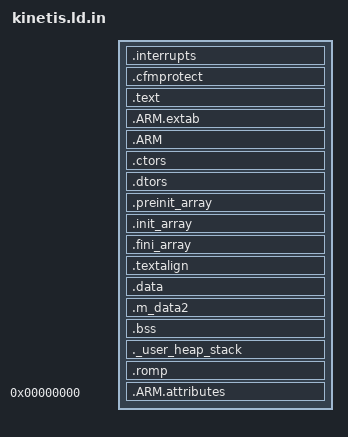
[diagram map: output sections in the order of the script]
/* ################################################################### */
/*##
/*##     This component was generated by some crappy tool and I modified
/*##     it to work with the K20 we are using. Deal with it.
/*##     This is now for the MK20DX128VLH7 with 128k flash and 32k SRAM
/*##     - Ben Nahill<bnahill@gmail.com>
/*## 
/*##     THIS COMPONENT MODULE IS GENERATED BY THE TOOL. DO NOT MODIFY IT. */
/*##                                   */
/*##     Filename  : ProcessorExpert.ld */
/*##                                   */
/*##     Project   : ProcessorExpert   */
/*##                                   */
/*##     Processor : MK40DX256ZVLQ10   */
/*##                                   */
/*##     Compiler  : GNU C Compiler    */
/*##                                   */
/*##     Date/Time : 2013-02-26, 17:01, # CodeGen: 8 */
/*##                                   */
/*##     Abstract  :                   */
/*##                                   */
/*##     This file is used by the linker. It describes files to be linked, */
/*##     memory ranges, stack size, etc. For detailed description about linker */
/*##     command files see compiler documentation. This file is generated by default. */
/*##     You can switch off generation by setting the property "Generate linker file = no" */
/*##     in the "Build options" tab of the CPU component and then modify this file as needed. */
/*##
/*##                                   */
/*## ###################################################################*/


/* Entry Point */
ENTRY(__reset_vector)

/* Highest address of the user mode stack */
_estack = 0x20000000;    /* end of m_data */
__SP_INIT = _estack;
__stack = _estack; /* For newlib */

/* Generate a link error if heap and stack don't fit into RAM */
__heap_size = 2k;                 /* required amount of heap  */
__stack_size = 8k;                 /* required amount of stack */


MEMORY {
  /* Vector addresses in the first 1K */
  m_interrupts (RX) : ORIGIN = 0x00000000, LENGTH = 1k
  /* Then some flash protection crap */
  m_cfmprotrom  (RX) : ORIGIN = 0x00000400, LENGTH = 16
  /* Then the flash we actually want */
  m_text      (RX) : ORIGIN = 1k + 32, LENGTH = ${FLASH_SIZE} - 32
  /* There are two RAM regions... They are centered around 0x20000000 */
  m_data      (RW) : ORIGIN = 0x20000000 - ${SRAM_BANK_SIZE}, LENGTH = ${SRAM_BANK_SIZE}
  /* To avoid variables crossing this boundary, they are separated.
   * Hopefully this won't screw something up.
   */
  m_data2     (RW) : ORIGIN = 0x20000000, LENGTH = ${SRAM_BANK_SIZE}
}

/* Define output sections */
SECTIONS
{
  /* The startup code goes first into INTERNAL_FLASH */
  .interrupts :
  {
    __vector_table = .;
    . = ALIGN(4);
    KEEP(*(.vectortable)) /* Startup code */
    . = ALIGN(4);
  } > m_interrupts

  .cfmprotect :
  {
        KEEP(*(.cfmconfig))     /* Flash Configuration Field (FCF) */
		. = ALIGN(4);
  } > m_cfmprotrom

  /* The program code and other data goes into INTERNAL_FLASH */
  .text :
  {
	. = ALIGN(4);
    *(.text .text* .gnu.linkonce.t.*)           /* .text sections (code) */
    *(.rodata .rodata* .gnu.linkonce.r.*)         /* .rodata sections (constants, strings, etc.) */
    *(.gnu.warning)
    *(.plt)
    *(.glue_7 .glue_7t)         /* glue arm to thumb code */
    *(.eh_frame)

    KEEP (*(.init))
    KEEP (*(.fini))

    . = ALIGN(4);
    _etext = .;        /* define a global symbols at end of code */
  } > m_text

   .ARM.extab   : { *(.ARM.extab* .gnu.linkonce.armextab.*) } > m_text
    .ARM : {
    __exidx_start = .;
      *(.ARM.exidx*)
      __exidx_end = .;
  } > m_text

 .ctors :
  {
    __CTOR_LIST__ = .;
    /* gcc uses crtbegin.o to find the start of
       the constructors, so we make sure it is
       first.  Because this is a wildcard, it
       doesn't matter if the user does not
       actually link against crtbegin.o; the
       linker won't look for a file to match a
       wildcard.  The wildcard also means that it
       doesn't matter which directory crtbegin.o
       is in.  */
    KEEP (*crtbegin.o(.ctors))
    /* We don't want to include the .ctor section from
       from the crtend.o file until after the sorted ctors.
       The .ctor section from the crtend file contains the
       end of ctors marker and it must be last */
    KEEP (*(EXCLUDE_FILE (*crtend.o ) .ctors))
    KEEP (*(SORT(.ctors.*)))
    KEEP (*crtend.o(.ctors))
    KEEP (*crtbegin.o(.dtors))
    KEEP (*(EXCLUDE_FILE(crtend.o) .dtors))
    KEEP (*(SORT(.dtors)))
    KEEP (*crtend.o(.dtors))
    __CTOR_END__ = .;
  } > m_text

  .dtors :
  {
    __DTOR_LIST__ = .;
    KEEP (*crtbegin.o(.dtors))
    KEEP (*(EXCLUDE_FILE (*crtend.o ) .dtors))
    KEEP (*(SORT(.dtors.*)))
    KEEP (*(.dtors))
    __DTOR_END__ = .;
  } > m_text

  .preinit_array     :
  {
    PROVIDE_HIDDEN (__preinit_array_start = .);
    KEEP (*(.preinit_array*))
    PROVIDE_HIDDEN (__preinit_array_end = .);
  } > m_text
  .init_array :
  {
    PROVIDE_HIDDEN (__init_array_start = .);
    KEEP (*(SORT(.init_array.*)))
    KEEP (*(.init_array*))
    PROVIDE_HIDDEN (__init_array_end = .);
  } > m_text
  .fini_array :
  {
    PROVIDE_HIDDEN (__fini_array_start = .);
    KEEP (*(SORT(.fini_array.*)))
    KEEP (*(.fini_array*))
    PROVIDE_HIDDEN (__fini_array_end = .);

        ___ROM_AT = .;
  } > m_text

  .textalign : ONLY_IF_RO
  {
    . = ALIGN(8);
  } > m_text
  
  _etext = .;
  _textdata = _etext;

  /* Initialized data sections goes into RAM, load LMA copy after code */
  .data : AT(___ROM_AT)
  {
    . = ALIGN(4);
    _sdata = .;        /* create a global symbol at data start */
	PROVIDE(_data = .);
    *(.data)           /* .data sections */
    *(.data*)          /* .data* sections */
    *(.ramtext)
	PROVIDE(_edata = .);
    . = ALIGN(4);
    /* # Additional data content defined by components END */

    _edata = .;        /* define a global symbol at data end */
    PROVIDE(__end__ = .);
  } > m_data

  ___data_size = _edata - _sdata;

  ___m_data2_ROMStart = ___ROM_AT + SIZEOF(.data);
  .m_data2 : AT(___m_data2_ROMStart)
  {
     . = ALIGN(4);
	 ___m_data2_RAMStart = .;
	 . = ALIGN(512);
	 * (.usb_bdt)
	 . = ALIGN(0x4);
     *(.m_data2) /* This is an User defined section */
     ___m_data2_RAMEnd = .;
     . = ALIGN(4);
  } > m_data2
  ___m_data2_ROMSize = ___m_data2_RAMEnd - ___m_data2_RAMStart;



  /* Uninitialized data section */
  . = ALIGN(4);
  .bss :
  {
    /* This is used by the startup in order to initialize the .bss section */
    __START_BSS = .;
    __bss_start__ = __START_BSS;
    *(.bss .bss* .gnu.linkonce.b.*)
    *(COMMON)
    . = ALIGN(4);
    __END_BSS = .;
    __bss_end__ = __END_BSS;
  } > m_data
  PROVIDE(_estack = .);

  /* User_heap_stack section, used to check that there is enough RAM left */
  ._user_heap_stack :
  {
    . = ALIGN(4);
    PROVIDE ( end = . );
    PROVIDE ( _end = . );
    __heap_addr = .;
    . = . + __heap_size;
    . = . + __stack_size;
    . = ALIGN(4);
  } > m_data

  _romp_at = ___ROM_AT + SIZEOF(.data) +SIZEOF(.m_data2);
  .romp : AT(_romp_at)
  {
    __S_romp = _romp_at;
    LONG(___ROM_AT);
    LONG(_sdata);
    LONG(___data_size);
    LONG(___m_data2_ROMStart);
    LONG(___m_data2_RAMStart);
    LONG(___m_data2_ROMSize);
    LONG(0);
    LONG(0);
    LONG(0);
  }

  .ARM.attributes 0 : { *(.ARM.attributes) }
}


